# I3C0_VBP2APB_WRAP_CORE_VBP_MIPI_I3C_MST register map
Vendor: Texas Instruments
Peripheral module from a debugger description file (folder J7ES).
Registers are 32-bit, read-write, reset 0x0 unless marked. A register's access mark holds for its fields unless they carry their own. Offsets are as the file gives them; lines under a group give offsets from that group; [hi:lo] are bit positions; {n}, {i} and the like mark numbered series; 'fields as' and 'values as' point back to an identical list; <NAME> marks a mode.

## I3C0_VBP2APB_WRAP_CORE_VBP_MIPI_I3C_MST
0x00 I3C_DEV_ID ro reset 0x5034 — Return to the . This register holds the IP identifier.
  [15:0] DEV_ID — Unique IP identifier within Cadence IP portfolio
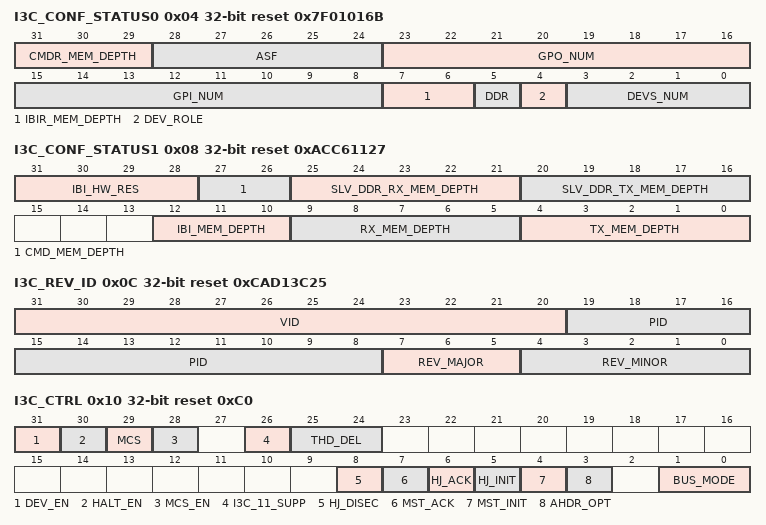
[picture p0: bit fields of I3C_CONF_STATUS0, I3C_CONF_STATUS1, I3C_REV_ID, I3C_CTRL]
0x04 I3C_CONF_STATUS0 ro reset 0x7F01016B — Return to the . The read-only Configuration Status Register 0 indicates the hardware configuration options chosen for implementation of the I3C-Master.
  [31:29] CMDR_MEM_DEPTH — CMD Resp MEM depth coded into 3 bits.
  [28:24] ASF — Indicates supported ASF checks.
  [23:16] GPO_NUM — Returns the value of User GPO
  [15:8] GPI_NUM — Returns the value of User GPI
  [7:6] IBIR_MEM_DEPTH — IBI Resp MEM depth coded into 2 bits.
  [5] DDR — Indicates if DDR is supported.
  [4] DEV_ROLE — Returns status of Device Role [Main/Secondary Master].
  [3:0] DEVS_NUM — Returns the number of retaining registers for I3C Slave devices [Addresses and Characteristics], the max value is 11.
0x08 I3C_CONF_STATUS1 ro reset 0xACC61127 — Return to the . The read-only Configuration Status Register 1 indicates the hardware configuration options chosen for implementation of the I3C-Master.
  [31:28] IBI_HW_RES — IBI resources
  [27:26] CMD_MEM_DEPTH — CMD FIFO depth coded into 3 bits.
  [25:21] SLV_DDR_RX_MEM_DEPTH — SLV DDR RX FIFO depth coded into 5 bits.
  [20:16] SLV_DDR_TX_MEM_DEPTH — SLV DDR TX FIFO depth coded into 5 bits.
  [12:10] IBI_MEM_DEPTH — IBI FIFO depth coded into 3 bits.
  [9:5] RX_MEM_DEPTH — RX FIFO depth coded into 5 bits.
  [4:0] TX_MEM_DEPTH — TX FIFO depth coded into 5 bits.
0x0C I3C_REV_ID ro reset 0xCAD13C25 — Return to the . This register gives an information about particular version of the IP.
  [31:20] VID — VENDOR_ID: IP vendor ID affected to CadenceIP [reset = 0xCAD].
  [19:8] PID — PRODUCT_ID: unique IP identifier within CDNS IP portfolio [reset = 0x13C].
  [7:5] REV_MAJOR — X: Major revision value.
  [4:0] REV_MINOR — Y: Minor revision value.
0x10 I3C_CTRL access per field reset 0xC0 — Return to the . Control Register for Cadence I3C Master IP - register that provides main control and configuration options for the controller.
  [31] DEV_EN rw — When set HIGH the I3C-Master is enabled and it can initiates the I3C/I2C transactions.
  [30] HALT_EN rw — Enable halt on abort behavior.
  [29] MCS wo — Manual Command Start writing 1 starts execution of the commands currently in CMD Memories.
  [28] MCS_EN rw — Manual Command Start Enable if set 1 the IP will wait with starting of command execution until MCS but [
  [26] I3C_11_SUPP rw — Enables support for timing parameter that has been changed in v1.1, i.e.
  [25:24] THD_DEL rw — Field that provides option to add data hold delay with respect to the SCL clock on which data on SDA is launched [applied only during actual Data transfer]
  [8] HJ_DISEC rw — This bit controls the HW response for ACK'ed HJ request.
  [7] MST_ACK rw — Specifies ACK response type for GETACCMST CCC, it can be either ACK response type [mst_ack = 1] or NACK response type [mst_ack = 0].
  [6] HJ_ACK rw — Specifies ACK response type for HJ request, it can be either ACK response type [hj_ack = 1] or NACK response type [hj_ack = 0].
  [5] HJ_INIT wo — Initiate HJ request - applicable only for Secondary master in slave mode.
  [4] MST_INIT wo — Initiate Mastership request - applicable only in slave mode.
  [3] AHDR_OPT rw — Enable[1]/Disable[0] the Address Header optimization.
  [1:0] BUS_MODE rw
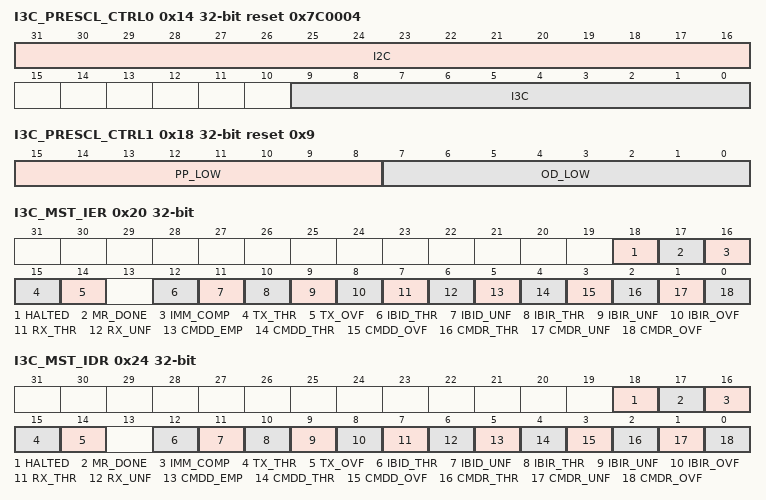
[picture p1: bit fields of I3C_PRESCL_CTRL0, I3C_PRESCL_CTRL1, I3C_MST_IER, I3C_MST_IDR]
0x14 I3C_PRESCL_CTRL0 access per field reset 0x7C0004 — Return to the . Prescale settings for SDR/I2C modes
  [31:16] I2C rw — Prescaler value for I2C SCL clock generation.
  [9:0] I3C rw — Prescaler value for I3C Push-Pull SDR Mode SCL clock generation.
0x18 I3C_PRESCL_CTRL1 reset 0x9 — Return to the . Prescale settings related to Open Drain / Push Pull I3C timings
  [15:8] PP_LOW — Counter for low period of SCL clock for Push Pull in I3C.
  [7:0] OD_LOW — Counter for low period of SCL clock for Open Drain in I3C.
0x20 I3C_MST_IER access per field — Return to the . The write only Interrupt Enable Register is used to enable interrupts by setting bits in the read only Interrupt Mask Register - Master Mode (). See Interrupt Status Register - Master Mode () description for details on specific interrupt conditions. When any bit is written high, the corresponding interrupt is enabled. Writing a low to any bit has no effect.
  [18] HALTED wo — Controller in halted state.
  [17] MR_DONE wo — Mastership handoff done Enable.
  [16] IMM_COMP wo — Immediate Commmand Completed Enable
  [15] TX_THR wo — Tx Data Threshold Enable.
  [14] TX_OVF wo — Tx Data MEM Underflow Enable
  [12] IBID_THR wo — IBI Data MEM threshold Enable.
  [11] IBID_UNF wo — IBI Data MEM underflow Enable.
  [10] IBIR_THR wo — IBI Response Queue threshold Enable
  [9] IBIR_UNF wo — IBI Response Queue underflow Enable
  [8] IBIR_OVF wo — IBI Response Queue onverflow Enable.
  [7] RX_THR wo — Rx Data MEM threshold Enable.
  [6] RX_UNF wo — Rx Data MEM underflow Enable.
  [5] CMDD_EMP wo — Command Request Queue Empty Enable.
  [4] CMDD_THR wo — Command Request Queue Threshold Enable.
  [3] CMDD_OVF wo — Command Request Queue Overflow Enable.
  [2] CMDR_THR wo — Command Response Queue Threshold Enable.
  [1] CMDR_UNF wo — Command Response Queue Underflow Enable.
  [0] CMDR_OVF wo — Command Response Queue Overflow Enable.
0x24 I3C_MST_IDR access per field — Return to the . The write only Interrupt Disable Register is used to disable interrupts by clearing the bits in the read only Interrupt Mask Register - Master Mode (). See Interrupt Status Register - Master Mode () description for details on specific interrupt conditions. When any bit is written high, the corresponding interrupt is disabled. Writing a low to any bit has no effect.
  [18] HALTED wo — Controller in halted state.
  [17] MR_DONE wo — Mastership handoff done Disable.
  [16] IMM_COMP wo — Immediate Commmand Completed Disable
  [15] TX_THR wo — Tx Data Threshold Disable.
  [14] TX_OVF wo — Tx Data MEM Underflow Disable
  [12] IBID_THR wo — IBI Data MEM threshold Disable.
  [11] IBID_UNF wo — IBI Data MEM underflow Disable.
  [10] IBIR_THR wo — IBI Response Queue threshold Disable
  [9] IBIR_UNF wo — IBI Response Queue underflow Disable
  [8] IBIR_OVF wo — IBI Response Queue onverflow Disable.
  [7] RX_THR wo — Rx Data MEM threshold Disable.
  [6] RX_UNF wo — Rx Data MEM underflow Disable.
  [5] CMDD_EMP wo — Command Request Queue Empty Disable.
  [4] CMDD_THR wo — Command Request Queue Threshold Disable.
  [3] CMDD_OVF wo — Command Request Queue Overflow Disable.
  [2] CMDR_THR wo — Command Response Queue Threshold Disable.
  [1] CMDR_UNF wo — Command Response Queue Underflow Disable.
  [0] CMDR_OVF wo — Command Response Queue Overflow Disable.
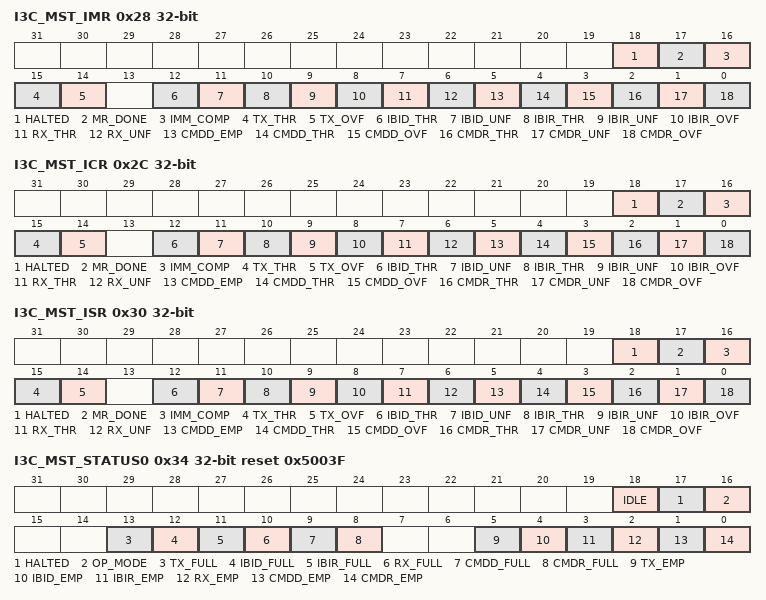
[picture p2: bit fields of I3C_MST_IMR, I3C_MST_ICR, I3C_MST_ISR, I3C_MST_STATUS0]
0x28 I3C_MST_IMR ro — Return to the . This read only register, indicates the current state of the interrupts mask. See Interrupt Status Register - Master Mode () description for details on specific interrupt conditions. A high value indicates the interrupt is enabled to generate an interrupt. A low value indicates the interrupt is disabled from generating an interrupt (masked).
  [18] HALTED — Controller in halted state.
  [17] MR_DONE — Mastership handoff done Mask.
  [16] IMM_COMP — Immediate Commmand Completed Mask
  [15] TX_THR — Tx Data Threshold Mask.
  [14] TX_OVF — Tx Data MEM Underflow Mask
  [12] IBID_THR — IBI Data MEM threshold Mask.
  [11] IBID_UNF — IBI Data MEM underflow Mask.
  [10] IBIR_THR — IBI Response Queue threshold Mask
  [9] IBIR_UNF — IBI Response Queue underflow Mask
  [8] IBIR_OVF — IBI Response Queue onverflow Mask.
  [7] RX_THR — Rx Data MEM threshold Mask.
  [6] RX_UNF — Rx Data MEM underflow Mask.
  [5] CMDD_EMP — Command Request Queue Empty Mask.
  [4] CMDD_THR — Command Request Queue Threshold Mask.
  [3] CMDD_OVF — Command Request Queue Overflow Mask.
  [2] CMDR_THR — Command Response Queue Threshold Mask.
  [1] CMDR_UNF — Command Response Queue Underflow Mask.
  [0] CMDR_OVF — Command Response Queue Overflow Mask.
0x2C I3C_MST_ICR access per field — Return to the . Interrupt Clear Register for Master Mode of the cdnsi3c_master controller. Write 1 to clear (change from 1 to 0) corresponding bit in . Writing 0 has no effect
  [18] HALTED wo — Controller is in halted state.
  [17] MR_DONE wo — Mastership handoff done Mask.
  [16] IMM_COMP wo — Immediate Commmand Completed Mask
  [15] TX_THR wo — Tx Data Threshold Mask.
  [14] TX_OVF wo — Tx Data MEM Underflow Mask
  [12] IBID_THR wo — IBI Data MEM threshold Mask.
  [11] IBID_UNF wo — IBI Data MEM underflow Mask.
  [10] IBIR_THR wo — IBI Response Queue threshold Mask
  [9] IBIR_UNF wo — IBI Response Queue underflow Mask
  [8] IBIR_OVF wo — IBI Response Queue onverflow Mask.
  [7] RX_THR wo — Rx Data MEM threshold Mask.
  [6] RX_UNF wo — Rx Data MEM underflow Mask.
  [5] CMDD_EMP wo — Command Request Queue Empty Mask.
  [4] CMDD_THR wo — Command Request Queue Threshold Mask.
  [3] CMDD_OVF wo — Command Request Queue Overflow Mask.
  [2] CMDR_THR wo — Command Response Queue Threshold Mask.
  [1] CMDR_UNF wo — Command Response Queue Underflow Mask.
  [0] CMDR_OVF wo — Command Response Queue Overflow Mask.
0x30 I3C_MST_ISR ro — Return to the . Interrupt Status Register for Master Mode of the cdnsi3c_master controller
  [18] HALTED — Controller in Halted state.
  [17] MR_DONE — Mastership handoff done.
  [16] IMM_COMP — Immediate Commmand Completed
  [15] TX_THR — Tx Data Threshold.
  [14] TX_OVF — Tx Data MEM overflow
  [12] IBID_THR — IBI Data MEM threshold.
  [11] IBID_UNF — IBI Data MEM underflow.
  [10] IBIR_THR — IBI Response Queue threshold
  [9] IBIR_UNF — IBI Response Queue underflow
  [8] IBIR_OVF — IBI Response Queue onverflow.
  [7] RX_THR — Rx Data MEM threshold.
  [6] RX_UNF — Rx Data MEM underflow.
  [5] CMDD_EMP — Command Request Queue Empty.
  [4] CMDD_THR — Command Request Queue Threshold.
  [3] CMDD_OVF — Command Request Queue Overflow.
  [2] CMDR_THR — Command Response Queue Threshold.
  [1] CMDR_UNF — Command Response Queue Underflow.
  [0] CMDR_OVF — Command Response Queue Overflow.
0x34 I3C_MST_STATUS0 access not given reset 0x5003F — Return to the . Status Register for Cadence I3C Master IP, meaningful only when controller operates in Master mode.
  [18] IDLE ro — Indicates when the core is IDLE and ready to accept new commands.
  [17] HALTED — Core Halted. (access RW1C)
  [16] OP_MODE ro — Indicates current mode of the controller:
  [13] TX_FULL ro
  [12] IBID_FULL ro
  [11] IBIR_FULL ro
  [10] RX_FULL ro
  [9] CMDD_FULL ro
  [8] CMDR_FULL ro
  [5] TX_EMP ro — TX Empty.
  [4] IBID_EMP ro — IBID Empty.
  [3] IBIR_EMP ro
  [2] RX_EMP ro — RX Empty.
  [1] CMDD_EMP ro — CMDD Empty.
  [0] CMDR_EMP ro
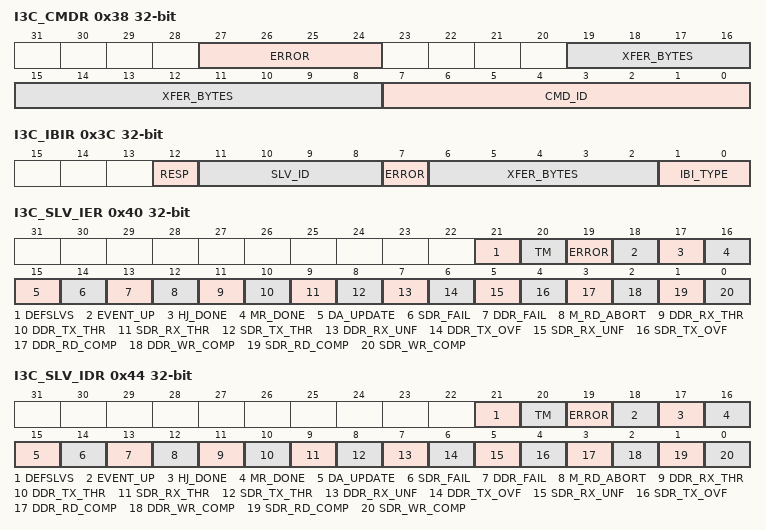
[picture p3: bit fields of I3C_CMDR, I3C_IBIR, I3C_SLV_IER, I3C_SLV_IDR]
0x38 I3C_CMDR ro — Return to the . Stores status on completion of each command, works on FIFO-basis.
  [27:24] ERROR — This field contains the code of an error that has occured during the last transaction.
  [19:8] XFER_BYTES — The number of transferred bytes [SDR] or transferred words [DDR] during the last command.
  [7:0] CMD_ID — CMD_ID - command identifier.
0x3C I3C_IBIR ro — Return to the . Stores status of SIR on its completion, works on FIFO-basis.
  [12] RESP — If HIGH IBI has been ACKed, NACK response otherwise
  [11:8] SLV_ID — ID of a Slave that has issued an IBI request
  [7] ERROR — Set to 1 if IBI Data FIFO overflow has occured during the transaction.
  [6:2] XFER_BYTES — Number of received DATA bytes.
  [1:0] IBI_TYPE — This field contains the type of an IBI.
0x40 I3C_SLV_IER wo — Return to the . The write only Interrupt Enable Register is used to enable interrupts by setting bits in the read only Interrupt Mask Register - Slave Mode (). See Interrupt Status Register - Slave Mode () description for details on specific interrupt conditions. When any bit is written high, the corresponding interrupt is enabled. Writing a low to any bit has no effect.
  [21] DEFSLVS — DEFSLVS interrupt Enable.
  [20] TM — TM interrupt Enable.
  [19] ERROR — ERROR interrupt Enable.
  [18] EVENT_UP — EVENT_UP interrupt Enable.
  [17] HJ_DONE — HJ_DONE interrupt Enable.
  [16] MR_DONE — MR_DONE interrupt Enable.
  [15] DA_UPDATE — DA_UPDATE interrupt Enable
  [14] SDR_FAIL — SDR_FAIL interrupt Enable
  [13] DDR_FAIL — DDR_FAIL interrupt Enable
  [12] M_RD_ABORT — M_RD_ABORT interrupt Enable.
  [11] DDR_RX_THR — DDR_RX_THR interrupt Enable.
  [10] DDR_TX_THR — DDR_TX_THR interrupt Enable.
  [9] SDR_RX_THR — SDR_RX_THR interrupt Enable.
  [8] SDR_TX_THR — SLV_SDR_TX_THR interrupt Enable.
  [7] DDR_RX_UNF — DDR_RX_UNF interrupt Enable.
  [6] DDR_TX_OVF — DDR_TX_OVF interrupt Enable.
  [5] SDR_RX_UNF — SDR_RX_UNF interrupt Enable.
  [4] SDR_TX_OVF — SDR_TX_OVF interrupt Enable.
  [3] DDR_RD_COMP — DDR_RD_COMP interrupt Enable.
  [2] DDR_WR_COMP — DDR_WR_COMP interrupt Enable.
  [1] SDR_RD_COMP — SDR_RD_COMP interrupt Enable.
  [0] SDR_WR_COMP — SDR_WR_COMP interrupt Enable.
0x44 I3C_SLV_IDR wo — Return to the . The write only Interrupt Disable Register is used to disable interrupts by clearing the bits in the read only Interrupt Mask Register - Slave Mode (). See Interrupt Status Register - Slave Mode () description for details on specific interrupt conditions. When any bit is written high, the corresponding interrupt is disabled. Writing a low to any bit has no effect.
  [21] DEFSLVS — DEFSLVS interrupt Disable.
  [20] TM — TM interrupt Disable.
  [19] ERROR — ERROR interrupt Disable.
  [18] EVENT_UP — EVENT_UP interrupt Disable.
  [17] HJ_DONE — HJ_DONE interrupt Disable.
  [16] MR_DONE — MR_DONE interrupt Disable.
  [15] DA_UPDATE — DA_UPDATE interrupt Disable.
  [14] SDR_FAIL — SDR_FAIL interrupt Disable
  [13] DDR_FAIL — DDR_FAIL interrupt Disable
  [12] M_RD_ABORT — M_RD_ABORT interrupt Disable.
  [11] DDR_RX_THR — DDR_RX_THR interrupt Disable.
  [10] DDR_TX_THR — DDR_TX_THR interrupt Disable.
  [9] SDR_RX_THR — SDR_RX_THR interrupt Disable.
  [8] SDR_TX_THR — SDR_TX_THR interrupt Disable.
  [7] DDR_RX_UNF — DDR_RX_UNF interrupt Disable.
  [6] DDR_TX_OVF — DDR_TX_OVF interrupt Disable.
  [5] SDR_RX_UNF — SDR_RX_UNF interrupt Disable.
  [4] SDR_TX_OVF — SDR_TX_OVF interrupt Disable.
  [3] DDR_RD_COMP — DDR_RD_COMP interrupt Disable.
  [2] DDR_WR_COMP — DDR_WR_COMP interrupt Disable.
  [1] SDR_RD_COMP — SDR_RD_COMP interrupt Disable.
  [0] SDR_WR_COMP — SDR_WR_COMP interrupt Disable.
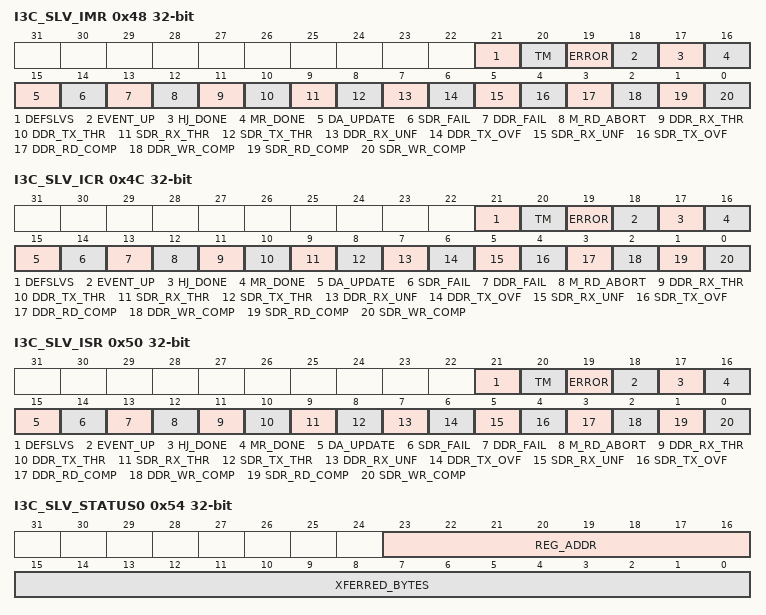
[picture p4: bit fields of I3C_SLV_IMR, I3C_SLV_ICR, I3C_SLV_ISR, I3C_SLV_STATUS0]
0x48 I3C_SLV_IMR ro — Return to the . This read only register, indicates the current state of the interrupts mask. See Interrupt Status Register - Slave Mode () description for details on specific interrupt conditions. A high value indicates the interrupt is enabled to generate an interrupt. A low value indicates the interrupt is disabled from generating an interrupt (masked).
  [21] DEFSLVS — DEFSLVS interrupt Mask.
  [20] TM — TM interrupt Mask.
  [19] ERROR — ERROR interrupt Mask.
  [18] EVENT_UP — EVENT_UP interrupt Mask.
  [17] HJ_DONE — HJ_DONE interrupt Mask.
  [16] MR_DONE — MR_DONE interrupt Mask.
  [15] DA_UPDATE — DA_UPDATE interrupt Mask.
  [14] SDR_FAIL — SDR_FAIL interrupt Mask
  [13] DDR_FAIL — DDR_FAIL interrupt Mask
  [12] M_RD_ABORT — M_RD_ABORT interrupt Mask.
  [11] DDR_RX_THR — DDR_RX_THR interrupt Mask.
  [10] DDR_TX_THR — DDR_TX_THR interrupt Mask.
  [9] SDR_RX_THR — SDR_RX_THR interrupt Mask.
  [8] SDR_TX_THR — SDR_TX_THR interrupt Mask.
  [7] DDR_RX_UNF — DDR_RX_UNF interrupt Mask.
  [6] DDR_TX_OVF — DDR_TX_OVF interrupt Mask.
  [5] SDR_RX_UNF — SDR_RX_UNF interrupt Mask.
  [4] SDR_TX_OVF — SDR_TX_OVF interrupt Mask.
  [3] DDR_RD_COMP — DDR_RD_COMP interrupt Mask.
  [2] DDR_WR_COMP — DDR_WR_COMP interrupt Mask.
  [1] SDR_RD_COMP — SDR_RD_COMP interrupt Mask.
  [0] SDR_WR_COMP — SDR_WR_COMP interrupt Mask.
0x4C I3C_SLV_ICR wo — Return to the . Interrupt Clear Register for Slave Mode of the cdnsi3c_master controller. Write 1 to clear (change from 1 to 0) corresponding bit in . Writing 0 has no effect
  [21] DEFSLVS — DEFSLVS interrupt Clear.
  [20] TM — TM interrupt Clear.
  [19] ERROR — ERROR interrupt Clear.
  [18] EVENT_UP — EVENT_UP interrupt Clear.
  [17] HJ_DONE — HJ_DONE interrupt Clear.
  [16] MR_DONE — MR_DONE interrupt Clear.
  [15] DA_UPDATE — DA_UPDATE interrupt Clear.
  [14] SDR_FAIL — SDR_FAIL interrupt Clear.
  [13] DDR_FAIL — DDR_FAIL interrupt Clear.
  [12] M_RD_ABORT — M_RD_ABORT interrupt Clear.
  [11] DDR_RX_THR — DDR_RX_THR interrupt Clear.
  [10] DDR_TX_THR — DDR_TX_THR interrupt Clear.
  [9] SDR_RX_THR — SDR_RX_THR interrupt Clear.
  [8] SDR_TX_THR — SDR_TX_THR interrupt Clear.
  [7] DDR_RX_UNF — DDR_RX_UNF interrupt Clear.
  [6] DDR_TX_OVF — DDR_TX_OVF interrupt Clear.
  [5] SDR_RX_UNF — SDR_RX_UNF interrupt Clear.
  [4] SDR_TX_OVF — SDR_TX_OVF interrupt Clear.
  [3] DDR_RD_COMP — DDR_RD_COMP interrupt Clear.
  [2] DDR_WR_COMP — DDR_WR_COMP interrupt Clear.
  [1] SDR_RD_COMP — SDR_RD_COMP interrupt Clear.
  [0] SDR_WR_COMP — SDR_WR_COMP interrupt Clear.
0x50 I3C_SLV_ISR ro — Return to the . Interrupt Status Register for Slave Mode of the cdnsi3c_master controller
  [21] DEFSLVS — This interrupt is triggered whenever I3C-Slave DEFSLVS CCC command is received.
  [20] TM — This interrupt is triggered whenever I3C-Slave is not in Test Mode and ENTTM CCC command with byte value of 0x01 [general Test Mode] is received.
  [19] ERROR — This event is triggered whenever SDR Error is detected - applicable for S0, S1, S2, S4 and S5 Errors from MIPI spec.
  [18] EVENT_UP — This event is triggered whenever DISEC CCC or ENEC CCC is received.
  [17] HJ_DONE — This event is triggered whenever Hot-Join request is completed.
  [16] MR_DONE — This event is triggered whenever Mastership Request is completed.
  [15] DA_UPDATE — This event is triggered whenever Dynamic Address of the device has been updated.
  [14] SDR_FAIL — This event is triggered whenever fail event during SDR transfer is detected [applicable for Private Write transfers only].
  [13] DDR_FAIL — This event is triggered whenever fail event during DDR transfer is detected.
  [12] M_RD_ABORT — Read Transfer Aborted by Master.
  [11] DDR_RX_THR — This event is triggered whenever threshold level for DDR Rx DATA Buffer is reached.
  [10] DDR_TX_THR — This event is triggered whenever threshold level for DDR Tx DATA Buffer is reached.
  [9] SDR_RX_THR — Rx DATA Buffer Threshold.
  [8] SDR_TX_THR — Tx DATA Buffer Threshold.
  [7] DDR_RX_UNF — Set if the host attempts to read from the DDR_RX_FIFO register when there is no more data.
  [6] DDR_TX_OVF — Set if the host attempts to write to DDR_TX_FIFO register more times than the FIFO depth.
  [5] SDR_RX_UNF — Rx DATA Buffer Underflow.
  [4] SDR_TX_OVF — Tx DATA Buffer Overflow.
  [3] DDR_RD_COMP — This bit is set whenever the Slave terminates the DDR Read transfer.
  [2] DDR_WR_COMP — This bit is set whenever the Master terminates the DDR Write transfer.
  [1] SDR_RD_COMP — This bit is set whenever the Slave terminates the SDR Private Read transfer.
  [0] SDR_WR_COMP — This bit is set whenever the Master terminates the SDR Private Write transfer.
0x54 I3C_SLV_STATUS0 ro — Return to the . The read only Status 0 register () is provided to enable the continuous monitoring of the raw unmasked status information of the I3C-Master operating in Slave mode.
  [23:16] REG_ADDR — Private Read/Write Address.
  [15:0] XFERRED_BYTES — Number of transferred bytes in SDR transactions.
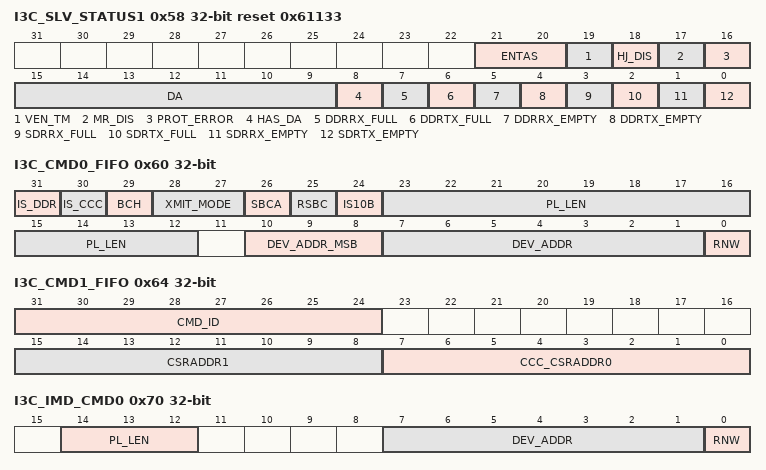
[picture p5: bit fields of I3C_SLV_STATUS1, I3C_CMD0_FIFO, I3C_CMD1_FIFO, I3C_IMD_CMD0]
0x58 I3C_SLV_STATUS1 ro reset 0x61133 — Return to the . The read only Status 1 register () is provided to enable the continuous monitoring of the raw unmasked status information of the I3C-Master operating in Slave mode.
  [21:20] ENTAS — Bits that indicate current Activity State.
  [19] VEN_TM — Vendor Test Mode.
  [18] HJ_DIS — Hot-Join Disabled.
  [17] MR_DIS — This bit is set whenever MR request is disabled by Current I3C-Master using DISEC CCC.
  [16] PROT_ERROR — Protocol Error Condition Indicator.
  [15:9] DA — Slave Dynamic Address.
  [8] HAS_DA — This bit is set whenever Slave has Dynamic Address assigned.
  [7] DDRRX_FULL — This bit is set whenever
  [6] DDRTX_FULL — This bit is set whenever
  [5] DDRRX_EMPTY — This bit is set whenever
  [4] DDRTX_EMPTY — This bit is set whenever
  [3] SDRRX_FULL — This bit is set whenever SDR_RX_FIFO is full.
  [2] SDRTX_FULL — This bit is set whenever SDR_TX_FIFO is full.
  [1] SDRRX_EMPTY — This bit is set whenever SDR_RX_FIFO is empty.
  [0] SDRTX_EMPTY — This bit is set whenever SDR_TX_FIFO is empty.
0x60 I3C_CMD0_FIFO wo — Return to the . Command0 FIFO. When implemented, the commands will be executed sequentially in order of arrival from the FW.
  [31] IS_DDR — IS_DDR - DDR command.
  [30] IS_CCC
  [29] BCH — BCH - Broadcast Header.
  [28:27] XMIT_MODE — Defines transfer modes for I3C private read/write commands [not CCC], the following options are available:
  [26] SBCA — SBCA - Sixteen Bits CSR Addressing.
  [25] RSBC — RSBC - Repeated Start Between Commands.
  [24] IS10B — Is10B - Normal/Extended Address.
  [23:12] PL_LEN — PL_LEN - Payload Length.
  [10:8] DEV_ADDR_MSB — DEV_ADDR_MSB - legacy I2C Extended Address.
  [7:1] DEV_ADDR — DEV_ADDR - Static/Dynamic slave Address.
  [0] RNW — RnW - Read no Write.
0x64 I3C_CMD1_FIFO access per field — Return to the . Command 1 FIFO. When implemented, the commands will be executed sequentially in order of arrival from the FW.
  [31:24] CMD_ID wo — COMMAND ID - generated by the host and used by the DMA to sort incoming read data to different consumers [channelization].
  [15:8] CSRADDR1 wo — CSR ADDR
  [7:0] CCC_CSRADDR0 wo — CCC/CSR ADDR
0x68 I3C_TX_FIFO wo — Return to the . Tx Data FIFO which stores number of bytes to be sent with particular command. APB->I3C direction
  [31:0] DATA — Tx Data FIFO which stores number of bytes to be sent with particular command
0x70 I3C_IMD_CMD0 wo — Return to the . High priority command register. When the core currently is executing a particular command from the CMD FIFO and new immediate command is sent, the core finish the standard command and then will execute the immediate command, disregarding the CMD FIFO state. Supposed to be used mainly for CCC commands with payload up to 4 bytes.
  [14:12] PL_LEN — PL_LEN - Payload Length.
  [7:1] DEV_ADDR — DEV_ADDR - Static/Dynamic slave Address.
  [0] RNW — RnW - Read no Write.
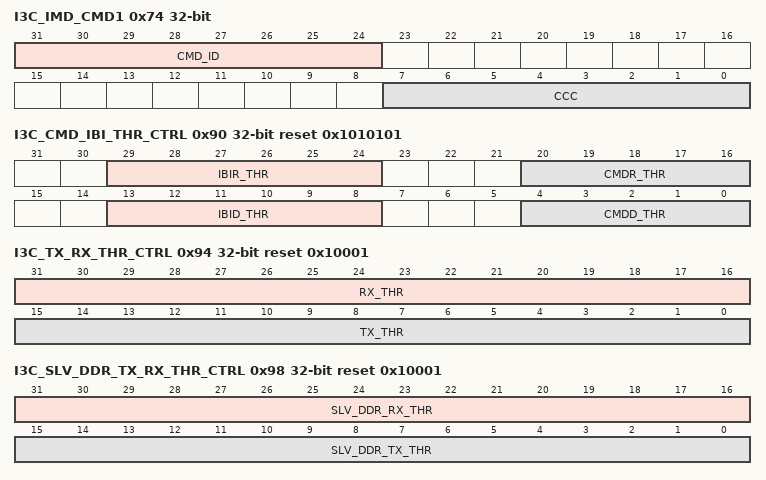
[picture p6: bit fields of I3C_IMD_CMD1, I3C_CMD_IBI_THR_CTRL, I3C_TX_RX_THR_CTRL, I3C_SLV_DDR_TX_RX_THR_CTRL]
0x74 I3C_IMD_CMD1 access per field — Return to the . High priority command register. When the core currently is executing a particular command from the CMD FIFO and new immediate command is sent, the core finish the standard command and then will execute the immediate command, disregarding the CMD FIFO state. Supposed to be used mainly for CCC commands with payload up to 4 bytes.
  [31:24] CMD_ID wo — COMMAND ID - generated by the host and used by the DMA to sort incoming read data to different consumers [channelization].
  [7:0] CCC wo — CCC code
0x78 I3C_IMD_DATA — Return to the . Payload/Data for a particular immediate command.
  [31:0] DATA — Payload/Data for a particular immediate command.
0x80 I3C_RX_FIFO ro — Return to the . Rx Data FIFO which stores number of bytes to be received with particular command. I3C->APB direction
  [31:0] DATA — Rx Data FIFO which stores number of bytes to be received with particular command.
0x84 I3C_IBI_DATA_FIFO ro — Return to the . IBI Data FIFO which stores number of bytes to be received for particular IBI request when BCR[2]=1 I3C->APB direction
  [31:0] DATA — IBI Data FIFO which stores number of bytes to be received for particular IBI request.
0x88 I3C_SLV_DDR_TX_FIFO wo — Return to the . DDR Tx Data FIFO stores number of words to be sent with particular DDR command in slave mode. APB->I3C direction
  [19:0] DDR_SLAVE_TX_DATA_FIFO — DDR Tx Data FIFO stores number of words to be sent with particular DDR command in slave mode
0x8C I3C_SLV_DDR_RX_FIFO ro — Return to the . DDR Rx Data FIFO stores number of words to be received with particular DDR command in slave mode. APB->I3C direction
  [19:0] DDR_SLAVE_RX_DATA_FIFO — DDR Rx Data FIFO stores number of words to be received with particular DDR command in slave mode
0x90 I3C_CMD_IBI_THR_CTRL access per field reset 0x1010101 — Return to the . Configuration register for Command and In-Band Interrupt data buffer thresholds.
  [29:24] IBIR_THR rw — Threshold configuration value for IBI RESP memory block
  [20:16] CMDR_THR rw — Threshold configuration value for Command RESP memory block
  [13:8] IBID_THR rw — Threshold configuration value for IBI DATA memory block
  [4:0] CMDD_THR rw — Threshold configuration value for Command REQ memory block
0x94 I3C_TX_RX_THR_CTRL reset 0x10001 — Return to the . Configuration register for Tx and Rx data buffer thresholds.
  [31:16] RX_THR — Threshold configuration value for Rx Data memory block
  [15:0] TX_THR — Threshold configuration value for Tx Data memory block
0x98 I3C_SLV_DDR_TX_RX_THR_CTRL reset 0x10001 — Return to the . Configuration register for Tx and Rx thresholds associated with Slave Mode DDR Data memory blocks.
  [31:16] SLV_DDR_RX_THR — Threshold configuration value for Slave Mode DDR Rx Data memory block
  [15:0] SLV_DDR_TX_THR — Threshold configuration value for Slave Mode DDR Tx Data memory block
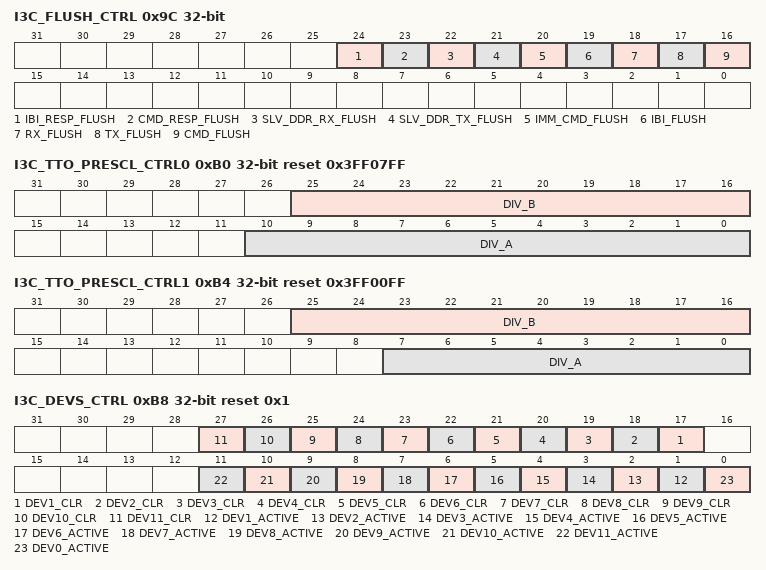
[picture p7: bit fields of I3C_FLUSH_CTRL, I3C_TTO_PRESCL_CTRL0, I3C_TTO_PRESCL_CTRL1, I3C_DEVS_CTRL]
0x9C I3C_FLUSH_CTRL wo — Return to the . Control register for FIFO soft flush control
  [24] IBI_RESP_FLUSH — When asserted while controller is disabled, the IBI Response Queue read/write pointers will be set to 0, effectively make the FIFO empty.
  [23] CMD_RESP_FLUSH — When asserted while controller is disabled, the Command Response Queue read/write pointers will be set to 0, effectively make the FIFO empty.
  [22] SLV_DDR_RX_FLUSH — When asserted while controller is disabled, the SLV DDR Rx Data memory block read/write pointers will be set to 0, effectively make the FIFO empty.
  [21] SLV_DDR_TX_FLUSH — When asserted while controller is disabled, the SLV DDR Tx Data memory block read/write pointers will be set to 0, effectively make the FIFO empty.
  [20] IMM_CMD_FLUSH — When asserted while controller is disabled, the immediate command/data register will be cleared.
  [19] IBI_FLUSH — When asserted while controller is disabled, the IBI data memory block read/write pointers will be set to 0.
  [18] RX_FLUSH — When asserted while controller is disabled, the Rx Data memory block read/write pointers will be set to 0.
  [17] TX_FLUSH — When asserted while controller is disabled, the Tx Data memory block read/write pointers will be set to 0.
  [16] CMD_FLUSH — When asserted while controller is disabled, the command Command memory block read/write pointers will be set to 0.
0xB0 I3C_TTO_PRESCL_CTRL0 access per field reset 0x3FF07FF — Return to the . Prescale settings for First SCL high timeout detection
  [25:16] DIV_B rw — Divider B
  [10:0] DIV_A rw — Divider A
0xB4 I3C_TTO_PRESCL_CTRL1 access per field reset 0x3FF00FF — Return to the . Prescale settings for SCL high and low timeout detection
  [25:16] DIV_B rw — Divider B
  [7:0] DIV_A rw — Divider A
0xB8 I3C_DEVS_CTRL access per field reset 0x1 — Return to the . Device control register
  [n+16] DEV{n}_CLR wo (n=1..11) — Clear DevID{n} retaining registers set.
  [n] DEV{n}_ACTIVE rw (n=1..11) — DevID{n} is active - has either valid DA or SA.
  [0] DEV0_ACTIVE ro — DevID0 is active - has either valid DA or SA.
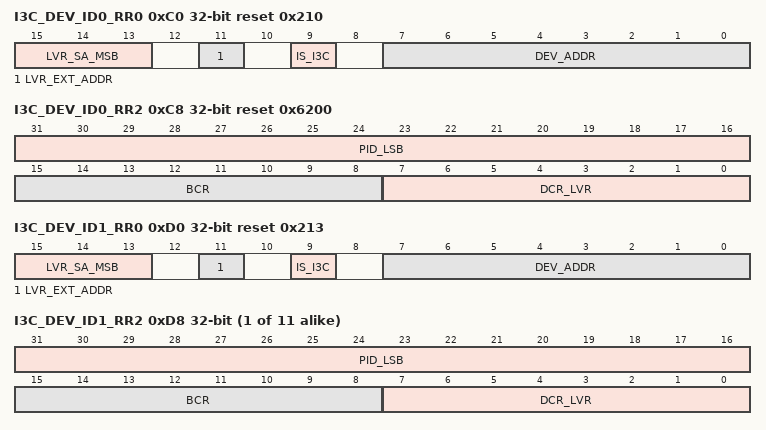
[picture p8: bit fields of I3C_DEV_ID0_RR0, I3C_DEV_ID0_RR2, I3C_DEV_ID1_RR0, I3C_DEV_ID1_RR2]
0xC0 I3C_DEV_ID0_RR0 access per field reset 0x210 — Return to the . Device ID 0 Retaining Register 0 : Configuration Register
  [15:13] LVR_SA_MSB rw — MSB bits of Legacy I2C Device with
  [11] LVR_EXT_ADDR rw — Device 0 Address mode used:
  [9] IS_I3C ro — Device 0 I3C mode Operation
  [7:0] DEV_ADDR rw — Device 0 Slave Dynamic [Static/Legacy] Address bits
0xC4 I3C_DEV_ID0_RR1 reset 0x2040000 — Return to the . Device ID 0 Retaining Register 1 : Provisional ID MSB 32-bits
  [31:0] PID_MSB — Device 0 48 to 16 Dev ID bits
0xC8 I3C_DEV_ID0_RR2 reset 0x6200 — Return to the . Device ID 0 Retaining Register 2 : Provisional ID LSB 16-bits, BCR, DCR or LVR (for legacy Mode)
  [31:16] PID_LSB — Device 0 15 to 0 Dev ID bits
  [15:8] BCR — Device 0 BCR register
  [7:0] DCR_LVR — Device 0 DCR [if I3C device] or LVR [if I2C device] register
0xD0 I3C_DEV_ID1_RR0 access per field reset 0x213 — Return to the . Device ID 1 Retaining Register 0 : Configuration Register
  [15:13] LVR_SA_MSB rw — MSB bits of Legacy I2C Device with
  [11] LVR_EXT_ADDR rw — Device 1 Address mode used:
  [9] IS_I3C rw — Device 1 I3C mode Operation
  [7:0] DEV_ADDR rw — Device 1 Slave Dynamic [Static/Legacy] Address bits
{0xC4+0x10*i} I3C_DEV_ID{i}_RR1 (i=1..11) — Return to the . Device ID {i} Retaining Register 1 : Provisional ID MSB 32-bits
  [31:0] PID_MSB — Device {i} 48 to 16 Dev ID bits
{0xC8+0x10*i} I3C_DEV_ID{i}_RR2 (i=1..11) — Return to the . Device ID {i} Retaining Register 2 : Provisional ID LSB 16-bits, BCR, DCR or LVR (for legacy Mode)
  [31:16] PID_LSB — Device {i} 15 to 0 Dev ID bits
  [15:8] BCR — Device {i} BCR register
  [7:0] DCR_LVR — Device {i} DCR [if I3C device] or LVR [if I2C device] register
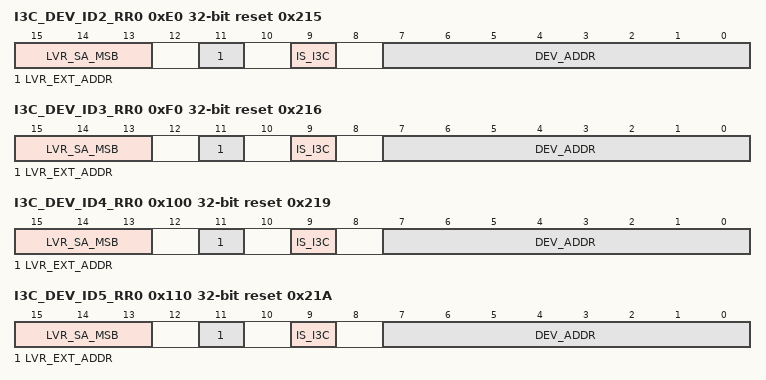
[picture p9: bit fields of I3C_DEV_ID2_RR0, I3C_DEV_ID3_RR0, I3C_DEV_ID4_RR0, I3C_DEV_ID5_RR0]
0xE0 I3C_DEV_ID2_RR0 access per field reset 0x215 — Return to the . Device ID 2 Retaining Register 0 : Configuration Register
  [15:13] LVR_SA_MSB rw — MSB bits of Legacy I2C Device with
  [11] LVR_EXT_ADDR rw — Device 2 Address mode used:
  [9] IS_I3C rw — Device 2 I3C mode Operation
  [7:0] DEV_ADDR rw — Device 2 Slave Dynamic [Static/Legacy] Address bits
0xF0 I3C_DEV_ID3_RR0 access per field reset 0x216 — Return to the . Device ID 3 Retaining Register 0 : Configuration Register
  [15:13] LVR_SA_MSB rw — MSB bits of Legacy I2C Device with
  [11] LVR_EXT_ADDR rw — Device 3 Address mode used:
  [9] IS_I3C rw — Device 3 I3C mode Operation
  [7:0] DEV_ADDR rw — Device 3 Slave Dynamic [Static/Legacy] Address bits
0x100 I3C_DEV_ID4_RR0 access per field reset 0x219 — Return to the . Device ID 4 Retaining Register 0 : Configuration Register
  [15:13] LVR_SA_MSB rw — MSB bits of Legacy I2C Device with
  [11] LVR_EXT_ADDR rw — Device 4 Address mode used:
  [9] IS_I3C rw — Device 4 I3C mode Operation
  [7:0] DEV_ADDR rw — Device 4 Slave Dynamic [Static/Legacy] Address bits
0x110 I3C_DEV_ID5_RR0 access per field reset 0x21A — Return to the . Device ID 5 Retaining Register 0 : Configuration Register
  [15:13] LVR_SA_MSB rw — MSB bits of Legacy I2C Device with
  [11] LVR_EXT_ADDR rw — Device 5 Address mode used:
  [9] IS_I3C rw — Device 5 I3C mode Operation
  [7:0] DEV_ADDR rw — Device 5 Slave Dynamic [Static/Legacy] Address bits
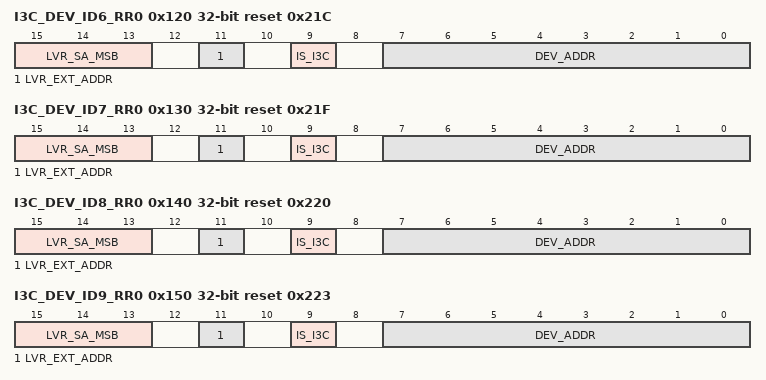
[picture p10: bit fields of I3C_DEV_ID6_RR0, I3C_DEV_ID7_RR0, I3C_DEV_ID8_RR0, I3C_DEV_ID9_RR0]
0x120 I3C_DEV_ID6_RR0 access per field reset 0x21C — Return to the . Device ID 6 Retaining Register 0 : Configuration Register
  [15:13] LVR_SA_MSB rw — MSB bits of Legacy I2C Device with
  [11] LVR_EXT_ADDR rw — Device 6 Address mode used:
  [9] IS_I3C rw — Device 6 I3C mode Operation
  [7:0] DEV_ADDR rw — Device 6 Slave Dynamic [Static/Legacy] Address bits
0x130 I3C_DEV_ID7_RR0 access per field reset 0x21F — Return to the . Device ID 7 Retaining Register 0 : Configuration Register
  [15:13] LVR_SA_MSB rw — MSB bits of Legacy I2C Device with
  [11] LVR_EXT_ADDR rw — Device 7 Address mode used:
  [9] IS_I3C rw — Device 7 I3C mode Operation
  [7:0] DEV_ADDR rw — Device 7 Slave Dynamic [Static/Legacy] Address bits
0x140 I3C_DEV_ID8_RR0 access per field reset 0x220 — Return to the . Device ID 8 Retaining Register 0 : Configuration Register
  [15:13] LVR_SA_MSB rw — MSB bits of Legacy I2C Device with
  [11] LVR_EXT_ADDR rw — Device 8 Address mode used:
  [9] IS_I3C rw — Device 8 I3C mode Operation
  [7:0] DEV_ADDR rw — Device 8 Slave Dynamic [Static/Legacy] Address bits
0x150 I3C_DEV_ID9_RR0 access per field reset 0x223 — Return to the . Device ID 9 Retaining Register 0 : Configuration Register
  [15:13] LVR_SA_MSB rw — MSB bits of Legacy I2C Device with
  [11] LVR_EXT_ADDR rw — Device 9 Address mode used:
  [9] IS_I3C rw — Device 9 I3C mode Operation
  [7:0] DEV_ADDR rw — Device 9 Slave Dynamic [Static/Legacy] Address bits
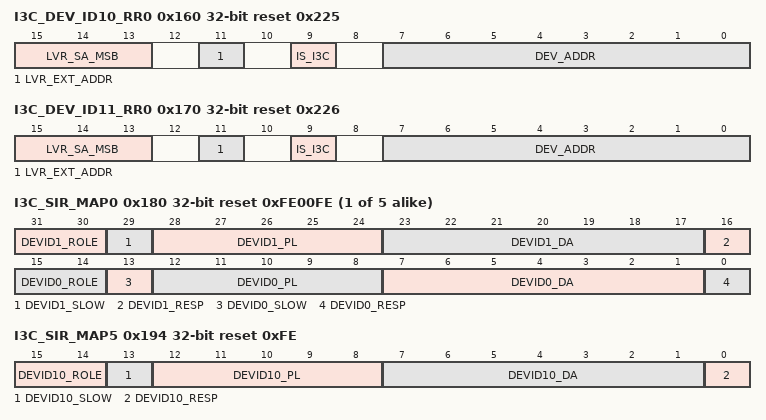
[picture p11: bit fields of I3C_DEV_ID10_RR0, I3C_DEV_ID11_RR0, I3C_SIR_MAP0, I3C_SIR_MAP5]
0x160 I3C_DEV_ID10_RR0 access per field reset 0x225 — Return to the . Device ID 10 Retaining Register 0 : Configuration Register
  [15:13] LVR_SA_MSB rw — MSB bits of Legacy I2C Device with
  [11] LVR_EXT_ADDR rw — Device 10 Address mode used:
  [9] IS_I3C rw — Device 10 I3C mode Operation
  [7:0] DEV_ADDR rw — Device 10 Slave Dynamic [Static/Legacy] Address bits
0x170 I3C_DEV_ID11_RR0 access per field reset 0x226 — Return to the . Device ID 11 Retaining Register 0 : Configuration Register
  [15:13] LVR_SA_MSB rw — MSB bits of Legacy I2C Device with
  [11] LVR_EXT_ADDR rw — Device 11 Address mode used:
  [9] IS_I3C rw — Device 11 I3C mode Operation
  [7:0] DEV_ADDR rw — Device 11 Slave Dynamic [Static/Legacy] Address bits
{0x180+4i} I3C_SIR_MAP{i} reset 0xFE00FE (i=0..4) — Return to the . Slave-initiated request Device ID Detection register{i}
  [31:30] DEVID{2i+1}_ROLE — Slave-initiated request Device ID{2i} BCR role
  [29] DEVID{2i+1}_SLOW — Slave-initiated request Device ID{2i} Max Data Speed Limitation
  [28:24] DEVID{2i+1}_PL — Slave-initiated request Device ID{2i} payload length
  [23:17] DEVID{2i+1}_DA — Slave-initiated request Device ID{2i} DA
  [16] DEVID{2i+1}_RESP — Slave-initiated request Device ID{2i} Ack/Nack response
  [15:14] DEVID{2i}_ROLE — Slave-initiated request Device ID{2i} BCR role
  [13] DEVID{2i}_SLOW — Slave-initiated request Device ID{2i} Max Data Speed Limitation
  [12:8] DEVID{2i}_PL — Slave-initiated request Device ID{2i} payload length
  [7:1] DEVID{2i}_DA — Slave-initiated request Device ID{2i} DA
  [0] DEVID{2i}_RESP — Slave-initiated request Device ID{2i} Ack/Nack response
0x194 I3C_SIR_MAP5 reset 0xFE — Return to the . Slave-initiated request Device ID Detection register5
  [15:14] DEVID10_ROLE — Slave-initiated request Device ID10 BCR role
  [13] DEVID10_SLOW — Slave-initiated request Device ID10 Max Data Speed Limitation
  [12:8] DEVID10_PL — Slave-initiated request Device ID10 payload length
  [7:1] DEVID10_DA — Slave-initiated request Device ID10 DA
  [0] DEVID10_RESP — Slave-initiated request Device ID10 Ack/Nack response
0x1A0 I3C_GPIR_WORD0 ro — Return to the . User Defined GPI Word 0: four 8-bits GPI Registers
  [7:0] GPI0 — User Defined GPI Register 0
0x220 I3C_GPOR_WORD0 ro — Return to the . User Defined GPO Word 0: four 8-bits GPO Registers
  [7:0] GPO0 — User Defined GPO Register 0
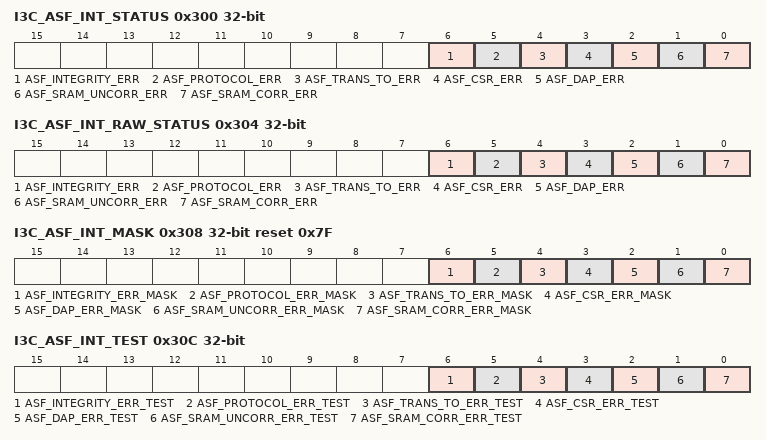
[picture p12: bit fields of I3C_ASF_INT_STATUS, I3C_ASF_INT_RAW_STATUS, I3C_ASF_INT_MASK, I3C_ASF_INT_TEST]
0x300 I3C_ASF_INT_STATUS access not given — Return to the . ASF Interrupt Status Register. This register indicates the source of ASF interrupts. The corresponding bit in the mask register must be clear for a bit to be set. If any bit is set in this register the asf_fatal or asf_nonfatal signal will be asserted. Writing to either raw or masked status registers, clear both registers. For test purposes, trigger signal interrupt event by writing to the ASF interrupt status test register.
  [6] ASF_INTEGRITY_ERR — Integrity error interrupt (access RW1C)
  [5] ASF_PROTOCOL_ERR — Protocol error interrupt (access RW1C)
  [4] ASF_TRANS_TO_ERR — Transaction timeouts error interrupt (access RW1C)
  [3] ASF_CSR_ERR — Configuration and status registers error interrupt (access RW1C)
  [2] ASF_DAP_ERR — Data and address paths parity error interrupt (access RW1C)
  [1] ASF_SRAM_UNCORR_ERR — SRAM uncorrectable error interrupt (access RW1C)
  [0] ASF_SRAM_CORR_ERR — SRAM correctable error interrupt (access RW1C)
0x304 I3C_ASF_INT_RAW_STATUS access not given — Return to the . ASF Interrupt Raw Status Register. A bit set in this raw register indicates a source of ASF fault in the corresponding feature. Writing to either raw or masked status registers, clear both registers. For test purposes, trigger signal interrupt event by writing to the ASF interrupt status test register.
  fields as I3C_ASF_INT_STATUS
0x308 I3C_ASF_INT_MASK access per field reset 0x7F — Return to the . The ASF interrupt mask register indicating which interrupt bits in the ASF interrupt status register are masked. All bits are set at reset. Clear the individual bit to enable the corresponding interrupt.
  [6] ASF_INTEGRITY_ERR_MASK rw — Mask bit for integrity error interrupt
  [5] ASF_PROTOCOL_ERR_MASK rw — Mask bit for protocol error interrupt.
  [4] ASF_TRANS_TO_ERR_MASK rw — Mask bit for transaction timeouts error interrupt.
  [3] ASF_CSR_ERR_MASK rw — Mask bit for configuration and status registers error interrupt.
  [2] ASF_DAP_ERR_MASK rw — Mask bit for data and address paths parity error interrupt.
  [1] ASF_SRAM_UNCORR_ERR_MASK rw — Mask bit for SRAM uncorrectable error interrupt.
  [0] ASF_SRAM_CORR_ERR_MASK rw — Mask bit for SRAM correctable error interrupt.
0x30C I3C_ASF_INT_TEST access per field — Return to the . The ASF interrupt test register emulate hardware even. Write one to individual bit to trigger single event in (masked and raw) status registers according to mask and will generate interrupt accordingly.
  [6] ASF_INTEGRITY_ERR_TEST wo — Test bit for integrity error interrupt
  [5] ASF_PROTOCOL_ERR_TEST wo — Test bit for protocol error interrupt.
  [4] ASF_TRANS_TO_ERR_TEST wo — Test bit for transaction timeouts error interrupt.
  [3] ASF_CSR_ERR_TEST wo — Test bit for configuration and status registers error interrupt.
  [2] ASF_DAP_ERR_TEST wo — Test bit for data and address paths parity error interrupt.
  [1] ASF_SRAM_UNCORR_ERR_TEST wo — Test bit for SRAM uncorrectable error interrupt.
  [0] ASF_SRAM_CORR_ERR_TEST wo — Test bit for SRAM correctable error interrupt.
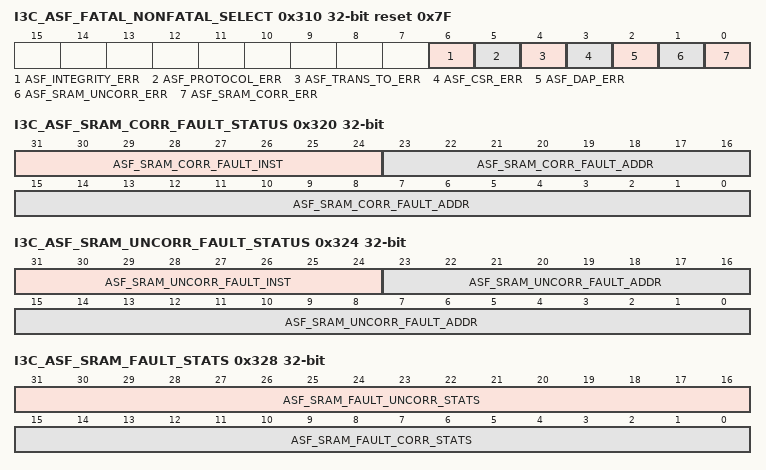
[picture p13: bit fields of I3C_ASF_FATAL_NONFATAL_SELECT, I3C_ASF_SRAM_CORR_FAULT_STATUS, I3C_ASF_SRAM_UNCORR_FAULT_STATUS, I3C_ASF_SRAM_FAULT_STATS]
0x310 I3C_ASF_FATAL_NONFATAL_SELECT access per field reset 0x7F — Return to the . The fatal or non-fatal interrupt register selects whether a fatal (asf_int_fatal) or non-fatal (asf_int_nonfatal) interrupt is triggered. If the bit of the event will be set to one then fatal interrupt (asf_int_fatal) will be triggered. Otherwise the non-fatal interrupt (asf_int_nonfatal) will be triggered.
  [6] ASF_INTEGRITY_ERR rw — Enable integrity error interrupt as fatal
  [5] ASF_PROTOCOL_ERR rw — Enable protocol error interrupt as fatal.
  [4] ASF_TRANS_TO_ERR rw — Enable transaction timeouts error interrupt as fatal.
  [3] ASF_CSR_ERR rw — Enable configuration and status registers error interrupt as fatal.
  [2] ASF_DAP_ERR rw — Enable data and address paths parity error interrupt as fatal.
  [1] ASF_SRAM_UNCORR_ERR rw — Enable SRAM uncorrectable error interrupt as fatal.
  [0] ASF_SRAM_CORR_ERR rw — Enable SRAM correctable error interrupt as fatal.
0x320 I3C_ASF_SRAM_CORR_FAULT_STATUS ro — Return to the . Status register for SRAM correctable fault. These fields are updated whenever asf_sram_corr_fault input is active.
  [31:24] ASF_SRAM_CORR_FAULT_INST — Last SRAM instance that generated fault.
  [23:0] ASF_SRAM_CORR_FAULT_ADDR — Last SRAM address that generated fault.
0x324 I3C_ASF_SRAM_UNCORR_FAULT_STATUS ro — Return to the . Status register for SRAM uncorrectable fault. These fields are updated whenever asf_sram_uncorr_fault input is active.
  [31:24] ASF_SRAM_UNCORR_FAULT_INST — Last SRAM instance that generated fault.
  [23:0] ASF_SRAM_UNCORR_FAULT_ADDR — Last SRAM address that generated fault.
0x328 I3C_ASF_SRAM_FAULT_STATS access not given — Return to the . Statistics register for SRAM faults. Note that this register clears when software writes to any field.
  [31:16] ASF_SRAM_FAULT_UNCORR_STATS — Count of number of uncorrectable errors if implemented. (access RW1C)
  [15:0] ASF_SRAM_FAULT_CORR_STATS — Count of number of correctable errors if implemented. (access RW1C)
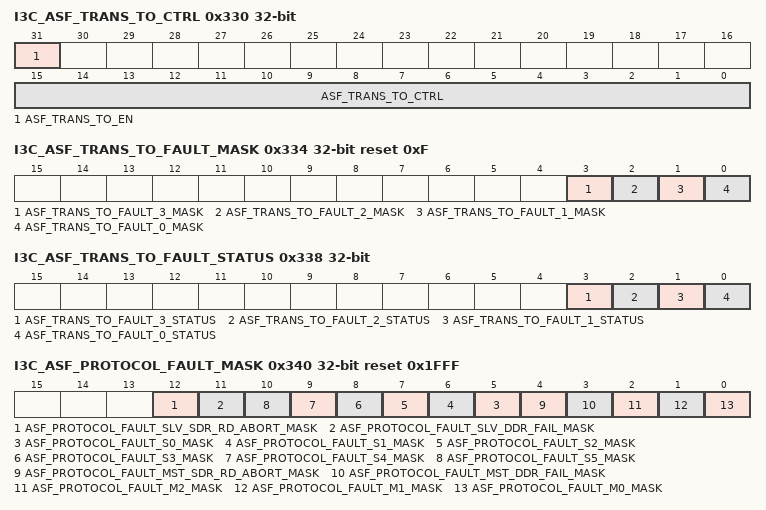
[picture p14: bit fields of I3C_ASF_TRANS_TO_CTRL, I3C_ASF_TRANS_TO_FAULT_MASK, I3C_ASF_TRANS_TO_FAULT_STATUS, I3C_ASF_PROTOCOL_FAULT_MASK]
0x330 I3C_ASF_TRANS_TO_CTRL access per field — Return to the . Control register to configure the ASF transaction timeout monitors.
  [31] ASF_TRANS_TO_EN rw — Enable transaction timeout monitoring.
  [15:0] ASF_TRANS_TO_CTRL rw — Timer value to use for transaction timeout monitor.
0x334 I3C_ASF_TRANS_TO_FAULT_MASK access per field reset 0xF — Return to the . Control register to mask out ASF transaction timeout faults from triggering interrupts. On reset, all bits are set to mask out all sources. Clear the corresponding bit to enable the interrupt source. The width of this field is parameterizable and the bit definitions are implementation specific.
  [3] ASF_TRANS_TO_FAULT_3_MASK rw — Mask bit for apb transaction timeout fault.
  [2] ASF_TRANS_TO_FAULT_2_MASK rw — Mask bit for I3C transaction SCL low timeout fault.
  [1] ASF_TRANS_TO_FAULT_1_MASK rw — Mask bit for I3C transaction SCL high timeout fault.
  [0] ASF_TRANS_TO_FAULT_0_MASK rw — Mask bit for I3C transaction first SCL high timeout fault.
0x338 I3C_ASF_TRANS_TO_FAULT_STATUS access not given — Return to the . Status register for transaction timeouts fault. If a fault occurs the relevant status bit will be set to 1. Each bit can be cleared by software writing 1 to each bit.
  [3] ASF_TRANS_TO_FAULT_3_STATUS — Status bits for apb transaction timeout fault. (access RW1C)
  [2] ASF_TRANS_TO_FAULT_2_STATUS — Status bits for I3C transaction SCL low timeout fault. (access RW1C)
  [1] ASF_TRANS_TO_FAULT_1_STATUS — Status bits for I3C transaction SCL high timeout fault. (access RW1C)
  [0] ASF_TRANS_TO_FAULT_0_STATUS — Status bits for I3C transaction first SCL high timeout fault. (access RW1C)
0x340 I3C_ASF_PROTOCOL_FAULT_MASK access per field reset 0x1FFF — Return to the . Control register to mask out ASF Protocol faults from triggering interrupts. On reset, all bits are set to mask out all sources. Clear the corresponding bit to enable the interrupt source. The width of this field is parameterisable and the bit definitions are implementation specific.
  [12] ASF_PROTOCOL_FAULT_SLV_SDR_RD_ABORT_MASK rw — Mask bit for slv_sdr_rd_abort protocol fault source.
  [11] ASF_PROTOCOL_FAULT_SLV_DDR_FAIL_MASK rw — Mask bit for slv_ddr_fail protocol fault source.
  [n+5] ASF_PROTOCOL_FAULT_S{n}_MASK rw (n=0..5) — Mask bit for s{n} protocol fault source.
  [4] ASF_PROTOCOL_FAULT_MST_SDR_RD_ABORT_MASK rw — Mask bit for mst_sdr_rd_abort protocol fault source.
  [3] ASF_PROTOCOL_FAULT_MST_DDR_FAIL_MASK rw — Mask bit for mst_ddr_fail protocol fault source.
  [2] ASF_PROTOCOL_FAULT_M2_MASK rw — Mask bit for m2 protocol fault source.
  [1] ASF_PROTOCOL_FAULT_M1_MASK rw — Mask bit for m1 protocol fault source.
  [0] ASF_PROTOCOL_FAULT_M0_MASK rw — Mask bit for m0 protocol fault source.
0x344 I3C_ASF_PROTOCOL_FAULT_STATUS access not given — Return to the . Status register for protocol faults. If a fault occurs the relevant status bit will be set to 1. Each bit can be cleared by software writing 1 to each bit
  [12] ASF_PROTOCOL_FAULT_SLV_SDR_RD_ABORT_STATUS — Status bit for slv_sdr_rd_abort protocol fault. (access RW1C)
  [11] ASF_PROTOCOL_FAULT_SLV_DDR_FAIL_STATUS — Status bit for slv_ddr_fail protocol fault. (access RW1C)
  [n+5] ASF_PROTOCOL_FAULT_S{n}_STATUS (n=0..5) — Status bit for s{n} protocol fault. (access RW1C)
  [4] ASF_PROTOCOL_FAULT_MST_SDR_RD_ABORT_STATUS — Status bit for mst_sdr_rd_abort protocol fault. (access RW1C)
  [3] ASF_PROTOCOL_FAULT_MST_DDR_FAIL_STATUS — Status bit for mst_ddr_fail protocol fault. (access RW1C)
  [2] ASF_PROTOCOL_FAULT_M2_STATUS — Status bit for m2 protocol fault. (access RW1C)
  [1] ASF_PROTOCOL_FAULT_M1_STATUS — Status bit for m1 protocol fault. (access RW1C)
  [0] ASF_PROTOCOL_FAULT_M0_STATUS — Status bit for m0 protocol fault. (access RW1C)
